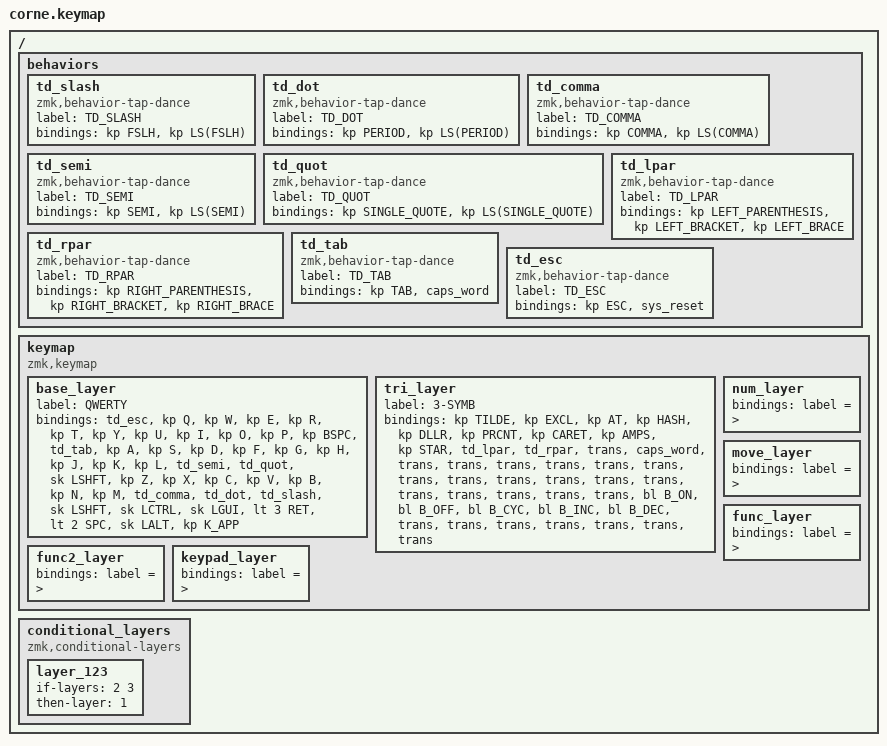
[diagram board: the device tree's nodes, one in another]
/*
 * Copyright (c) 2020 The ZMK Contributors
 *
 * SPDX-License-Identifier: MIT
 */

#include <behaviors.dtsi>
#include <dt-bindings/zmk/bt.h>
#include <dt-bindings/zmk/keys.h>
#include <dt-bindings/zmk/pointing.h>

#define BT0    (BT_CLR_CMD 0)
#define BT1    (BT_SEL_CMD 1)
#define BT2    (BT_SEL_CMD 2)
#define BT3    (BT_SEL_CMD 3)
#define BT4    (BT_SEL_CMD 4)
#define BTC    (BT_CLR_ALL)
#define B_ON   (BL_ON)
#define B_OFF  (BL_OFF)
#define B_CYC  (BL_CYCLE)
#define B_INC  (BL_INC)
#define B_DEC  (BL_DEC)
#define SCRLL  (SCRL_LEFT)
#define SCRLR  (SCRL_RIGHT)
#define SCRLU  (SCRL_UP)
#define SCRLD  (SCRL_DOWN)


/ {
    behaviors {
        td_slash: td_slash {
            compatible = "zmk,behavior-tap-dance";
            label = "TD_SLASH";
            #binding-cells = <0>;
            bindings = <&kp FSLH>, <&kp LS(FSLH)>;
        };

        td_dot: td_dot {
            compatible = "zmk,behavior-tap-dance";
            label = "TD_DOT";
            #binding-cells = <0>;
            bindings = <&kp PERIOD>, <&kp LS(PERIOD)>;
        };

        td_comma: td_comma {
            compatible = "zmk,behavior-tap-dance";
            label = "TD_COMMA";
            #binding-cells = <0>;
            bindings = <&kp COMMA>, <&kp LS(COMMA)>;
        };

        td_semi: td_semi {
            compatible = "zmk,behavior-tap-dance";
            label = "TD_SEMI";
            #binding-cells = <0>;
            bindings = <&kp SEMI>, <&kp LS(SEMI)>;
        };

        td_quot: td_quot {
            compatible = "zmk,behavior-tap-dance";
            label = "TD_QUOT";
            #binding-cells = <0>;
            bindings = <&kp SINGLE_QUOTE>, <&kp LS(SINGLE_QUOTE)>;
        };

        td_lpar: td_lpar {
            compatible = "zmk,behavior-tap-dance";
            label = "TD_LPAR";
            #binding-cells = <0>;
            bindings =
                <&kp LEFT_PARENTHESIS>,
                <&kp LEFT_BRACKET>,
                <&kp LEFT_BRACE>;
        };

        td_rpar: td_rpar {
            compatible = "zmk,behavior-tap-dance";
            label = "TD_RPAR";
            #binding-cells = <0>;
            bindings =
                <&kp RIGHT_PARENTHESIS>,
                <&kp RIGHT_BRACKET>,
                <&kp RIGHT_BRACE>;
        };

        td_tab: td_tab {
            compatible = "zmk,behavior-tap-dance";
            label = "TD_TAB";
            #binding-cells = <0>;
            bindings = <&kp TAB>, <&caps_word>;
        };

        td_esc: td_esc {
            compatible = "zmk,behavior-tap-dance";
            label = "TD_ESC";
            #binding-cells = <0>;
            bindings = <&kp ESC>, <&sys_reset>;
        };
    };

    // --------------------------------------------------------------------------------
    // |  TAB |  Q  |  W  |  E  |  R  |  T  |   |  Y  |  U   |  I  |  O  |  P  | BSPC |
    // | CTRL |  A  |  S  |  D  |  F  |  G  |   |  H  |  J   |  K  |  L  |  ;  |  '   |
    // | SHFT |  Z  |  X  |  C  |  V  |  B  |   |  N  |  M   |  ,  |  .  |  /  | ESC  |
    //                    | CTL | GUI |4-SPC|   |2-ENT| ALT  | APP |
    // --------------------------------------------------------------------------------

    keymap {
        compatible = "zmk,keymap";
        base_layer {
            label = "QWERTY";
            bindings = <
//         |         |         |         |        ||         |         |         |         |         |         |         |
&td_esc     &kp Q    &kp W     &kp E     &kp R     &kp T     &kp Y     &kp U     &kp I     &kp O     &kp P     &kp BSPC
&td_tab     &kp A    &kp S     &kp D     &kp F     &kp G     &kp H     &kp J     &kp K     &kp L     &td_semi  &td_quot
&sk LSHFT   &kp Z    &kp X     &kp C     &kp V     &kp B     &kp N     &kp M     &td_comma &td_dot   &td_slash &sk LSHFT
                     &sk LCTRL &sk LGUI  &lt 3 RET &lt 2 SPC &sk LALT  &kp K_APP
            >;
        };

        tri_layer {
            label = "3-SYMB";
            bindings = <
//         |         |         |         |        ||         |         |         |         |         |         |         |
&kp TILDE  &kp EXCL  &kp AT    &kp HASH  &kp DLLR  &kp PRCNT &kp CARET &kp AMPS  &kp STAR  &td_lpar  &td_rpar  &trans
&caps_word &trans    &trans    &trans    &trans    &trans    &trans    &trans    &trans    &trans    &trans    &trans
&trans     &trans    &trans    &trans    &trans    &trans    &bl B_ON  &bl B_OFF &bl B_CYC &bl B_INC &bl B_DEC &trans
                               &trans    &trans    &trans    &trans    &trans    &trans
            >;
        };

        num_layer {
            bindings = <
            label = "R-NUMB";
//         |         |         |         |        ||         |         |         |         |         |         |         |
&kp GRAVE  &kp N1    &kp N2    &kp N3    &kp N4    &kp N5    &kp N6    &kp N7    &kp N8    &kp N9    &kp N0    &kp DEL
&caps_word &trans    &trans    &trans    &kp PIPE  &kp BSLH  &kp PLUS  &kp N4    &kp N5    &kp N6    &kp EQUAL &kp INS
&trans     &mo 6     &trans    &trans    &trans    &kp UNDER &kp MINUS &kp N1    &kp N2    &kp N3    &trans    &trans
                               &trans    &trans    &trans    &trans    &trans    &sl 4
            >;
        };

        move_layer {
            bindings = <
            label = "R-MOVE";
//         |         |         |         |        ||         |         |         |         |         |         |         |
&none      &none     &none     &msc SCRU &none     &none     &kp HOME  &none     &kp UP    &none     &kp PG_UP &trans
&none      &none     &msc SCRL &msc SCRD &msc SCRR &none     &kp END   &kp LEFT  &kp DOWN  &kp RIGHT &kp PG_DN &trans
&trans     &trans    &trans    &trans    &trans    &trans    &trans    &trans    &trans    &trans    &trans    &trans
                     &trans    &trans    &trans    &trans    &trans    &trans
            >;
        };

        func_layer {
            bindings = <
            label = "F1-F10";
//         |         |         |         |         |         |         |         |         |         |         |         |
&none      &kp F1    &kp F2    &kp F3    &kp F4    &kp F5    &kp F6    &kp F7    &kp F8    &kp F9    &kp F10   &none
&none      &none     &none     &none     &none     &none     &none     &kp F4    &kp F5    &kp F6    &none     &none
&bt BT_CLR &bt BT0   &bt BT1   &bt BT2   &bt BT3   &bt BT4   &none     &kp F1    &kp F2    &kp F3    &none     &none
                               &trans    &trans    &trans    &trans    &trans    &sl 5
            >;
        };

        func2_layer {
            bindings = <
            label = "F11-F24";
//         |         |         |         |         |         |         |         |         |         |         |         |
&none      &kp F11   &kp F12   &kp F13   &kp F14   &kp F15   &kp F16   &kp F17   &kp F18   &kp F19   &kp F20   &none
&none      &kp F21   &kp F22   &kp F23   &kp F24   &none     &kp F21   &kp F22   &kp F23   &kp F24   &none     &none
&none      &none     &none     &none     &none     &none     &none     &none     &none     &none     &none     &none
                     &trans    &trans   &trans     &trans    &trans    &trans
            >;
        };

        keypad_layer {
            bindings = <
            label = "KEYPD";
&none      &kp KP_N1  &kp KP_N2  &kp KP_N3  &kp KP_N4    &kp KP_N5    &kp KP_N6     &kp KP_N7  &kp KP_N8  &kp KP_N9  &kp KP_N0     &kp BSPC
&none      &none      &none      &none      &kp KP_LPAR  &kp KP_RPAR  &kp KP_PLUS   &kp KP_N4  &kp KP_N5  &kp KP_N6  &kp KP_EQUAL  &none
&kp LSHFT  &none      &none      &none      &kp KP_COMMA &kp KP_DOT   &kp KP_MINUS  &kp KP_N1  &kp KP_N2  &kp KP_N3  &kp KP_SLASH  &kp RSHFT
                                 &trans     &trans       &trans       &trans        &trans     &trans
            >;
        };
    };

    conditional_layers {
        compatible = "zmk,conditional-layers";

        layer_123 {
            if-layers = <2 3>;
            then-layer = <1>;
        };
    };
};
 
